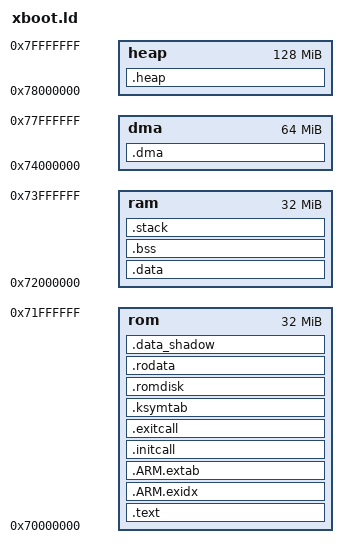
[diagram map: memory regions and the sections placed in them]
OUTPUT_FORMAT("elf32-littlearm", "elf32-bigarm", "elf32-littlearm")
OUTPUT_ARCH(arm)
ENTRY(_start)

STACK_UND_SIZE = 0x40000;
STACK_ABT_SIZE = 0x40000;
STACK_IRQ_SIZE = 0x40000;
STACK_FIQ_SIZE = 0x40000;
STACK_SRV_SIZE = 0x100000;

MEMORY
{
	rom  : org = 0x70000000, len = 32M
	ram  : org = 0x72000000, len = 32M
	dma  : org = 0x74000000, len = 64M
	heap : org = 0x78000000, len = 128M
}

SECTIONS
{
	.text :
	{
		PROVIDE(__image_start = .);
		PROVIDE(__text_start = .);
		.obj/arch/arm32/mach-realview/start.o (.text*)
		*(.text*)
		*(.init.text)
		*(.exit.text)
		*(.glue*)
		*(.note.gnu.build-id)
		PROVIDE(__text_end = .);
	} > rom

	.ARM.exidx ALIGN(8) :
	{
		PROVIDE (__exidx_start = .);
		*(.ARM.exidx*)
		PROVIDE (__exidx_end = .);
	} > rom

	.ARM.extab ALIGN(8) :
	{
		PROVIDE (__extab_start = .);
		*(.ARM.extab*)
		PROVIDE (__extab_end = .);
	} > rom

	.initcall ALIGN(8) :
	{
		PROVIDE(__initcall_start = .);
		KEEP(*(.initcall_0.text))
		KEEP(*(.initcall_1.text))
		KEEP(*(.initcall_2.text))
		KEEP(*(.initcall_3.text))
		KEEP(*(.initcall_4.text))
		KEEP(*(.initcall_5.text))
		KEEP(*(.initcall_6.text))
		KEEP(*(.initcall_7.text))
		KEEP(*(.initcall_8.text))
		KEEP(*(.initcall_9.text))
		PROVIDE(__initcall_end = .);
	} > rom

	.exitcall ALIGN(8) :
	{
		PROVIDE(__exitcall_start = .);
		KEEP(*(.exitcall_9.text))
		KEEP(*(.exitcall_8.text))
		KEEP(*(.exitcall_7.text))
		KEEP(*(.exitcall_6.text))
		KEEP(*(.exitcall_5.text))
		KEEP(*(.exitcall_4.text))
		KEEP(*(.exitcall_3.text))
		KEEP(*(.exitcall_2.text))
		KEEP(*(.exitcall_1.text))
		KEEP(*(.exitcall_0.text))
		PROVIDE(__exitcall_end = .);
	} > rom

	.ksymtab ALIGN(16) :
	{
		PROVIDE(__ksymtab_start = .);
		KEEP(*(.ksymtab.text))
		PROVIDE(__ksymtab_end = .);
	} > rom

	.romdisk ALIGN(8) :
	{
		PROVIDE(__romdisk_start = .);
		KEEP(*(.romdisk))
		PROVIDE(__romdisk_end = .);
	} > rom

	.rodata ALIGN(8) :
	{
		PROVIDE(__rodata_start = .);
		*(SORT_BY_ALIGNMENT(SORT_BY_NAME(.rodata*)))
		PROVIDE(__rodata_end = .);
	} > rom

	.data_shadow ALIGN(8) :
	{
		PROVIDE(__data_shadow_start = .);
		PROVIDE(__data_shadow_end = (. + SIZEOF(.data)));
		PROVIDE(__image_end = __data_shadow_end);
	} > rom

	.data : AT(ADDR(.data_shadow))
	{
		PROVIDE(__data_start = .);	
		*(.data*)
		. = ALIGN(8);
  		PROVIDE(__data_end = .);
	} > ram

	.bss ALIGN(8) (NOLOAD) :
	{
		PROVIDE(__bss_start = .);
		*(.bss*)
		*(.sbss*)
		*(COMMON)
		. = ALIGN(8);
		PROVIDE(__bss_end = .);
	} > ram

	.stack ALIGN(8) (NOLOAD) :
	{
		PROVIDE(__stack_start = .);
		PROVIDE(__stack_und_start = .);
		. += STACK_UND_SIZE;
		PROVIDE(__stack_und_end = .);
		. = ALIGN(8);
		PROVIDE(__stack_abt_start = .);
		. += STACK_ABT_SIZE;
		PROVIDE(__stack_abt_end = .);
		. = ALIGN(8);
		PROVIDE(__stack_irq_start = .);
		. += STACK_IRQ_SIZE;
		PROVIDE(__stack_irq_end = .);
		. = ALIGN(8);
		PROVIDE(__stack_fiq_start = .);
		. += STACK_FIQ_SIZE;
		PROVIDE(__stack_fiq_end = .);
		. = ALIGN(8);
		PROVIDE(__stack_srv_start = .);
		. += STACK_SRV_SIZE;
		PROVIDE(__stack_srv_end = .);
		. = ALIGN(8);
		PROVIDE(__stack_end = .);
	} > ram

	.dma ALIGN(8) (NOLOAD) :
	{
		PROVIDE(__dma_start = ORIGIN(dma));
		PROVIDE(__dma_end = ORIGIN(dma) + LENGTH(dma));
	} > dma

	.heap ALIGN(8) (NOLOAD) :
	{
		PROVIDE(__heap_start = ORIGIN(heap));
		PROVIDE(__heap_end = ORIGIN(heap) + LENGTH(heap));
	} > heap

	.stab 0 : { *(.stab) }
	.stabstr 0 : { *(.stabstr) }
	.stab.excl 0 : { *(.stab.excl) }
	.stab.exclstr 0 : { *(.stab.exclstr) }
	.stab.index 0 : { *(.stab.index) }
	.stab.indexstr 0 : { *(.stab.indexstr) }
	.comment 0 : { *(.comment) }
	.debug_abbrev 0 : { *(.debug_abbrev) }
	.debug_info 0 : { *(.debug_info) }
	.debug_line 0 : { *(.debug_line) }
	.debug_pubnames 0 : { *(.debug_pubnames) }
	.debug_aranges 0 : { *(.debug_aranges) }
}
